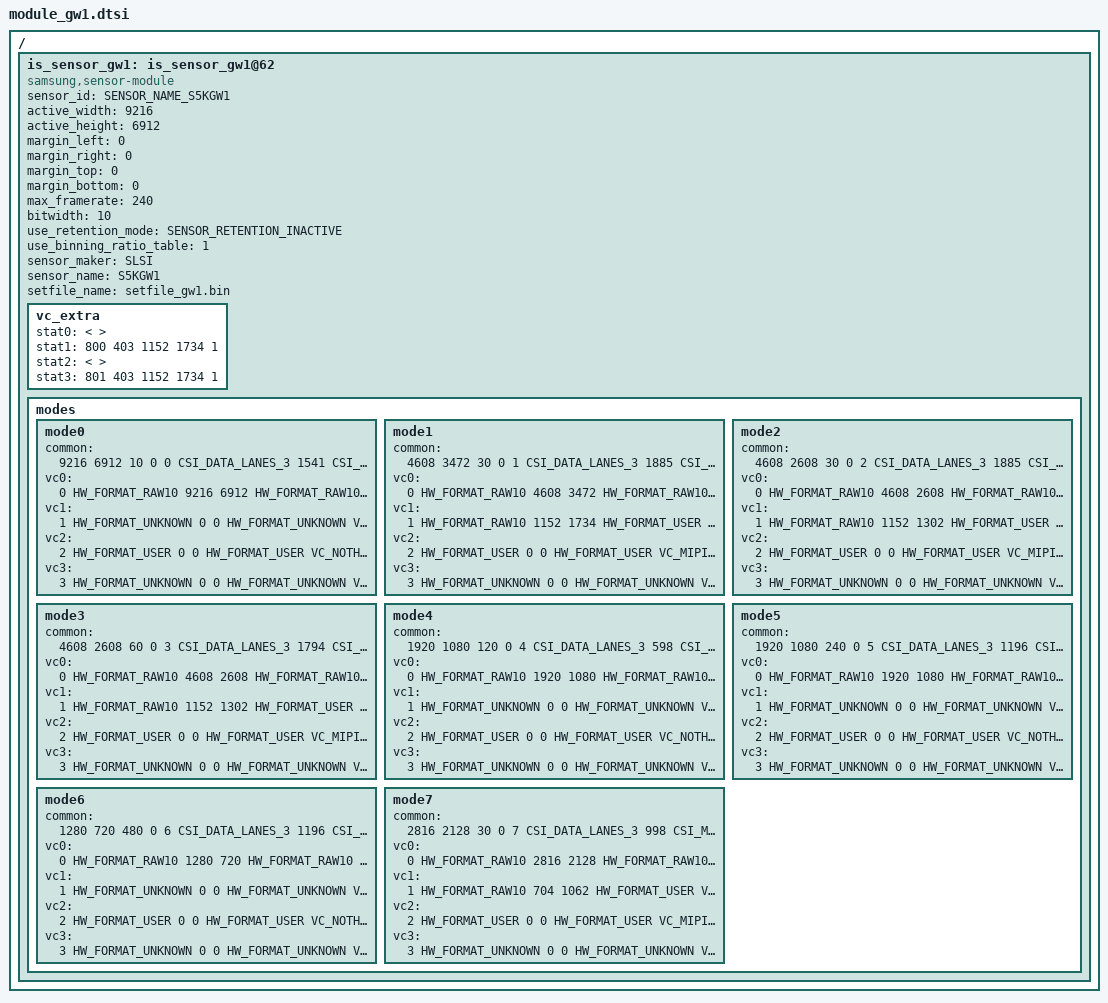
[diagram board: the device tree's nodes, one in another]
/*
 * SAMSUNG EXYNOSxxxx board camera device tree source
 *
 * Copyright (c) 2019 Samsung Electronics Co., Ltd.
 *		http://www.samsung.com
 *
 * This program is free software; you can redistribute it and/or modify
 * it under the terms of the GNU General Public License version 2 as
 * published by the Free Software Foundation.
 */

#include <dt-bindings/camera/exynos_is_dt.h>

/ {
	fragment@camera {
		target-path = "/";
		__overlay__ {
			is_sensor_gw1: is_sensor_gw1@62 {
				compatible = "samsung,sensor-module";

				/* common */
				sensor_id = <SENSOR_NAME_S5KGW1>;
				active_width = <9216>;
				active_height = <6912>;
				margin_left = <0>;
				margin_right = <0>;
				margin_top = <0>;
				margin_bottom = <0>;
				max_framerate = <240>;
				bitwidth = <10>;
				use_retention_mode = <SENSOR_RETENTION_INACTIVE>;
				use_binning_ratio_table = <1>;
				sensor_maker = "SLSI";
				sensor_name = "S5KGW1";
				setfile_name = "setfile_gw1.bin";

				status = "okay";

				vc_extra {
					/* ex) statX = <stat_type, sensor_mode, max_width, max_height, max_element> */
					stat0 = </* not avaliable */>;	/* VC_BUF_DATA_TYPE_SENSOR_STAT1 */
					stat1 = </* VC_STAT_TYPE_PDP_1_1_PDAF_STAT0 */ 800 /* VC_SENSOR_MODE_SUPER_PD_2_TAIL */ 403 1152 1734 1>; /* VC_BUF_DATA_TYPE_GENERAL_STAT1 */
					stat2 = </* not avaliable */>;	/* VC_BUF_DATA_TYPE_SENSOR_STAT2 */
					stat3 = </* VC_STAT_TYPE_PDP_1_1_PDAF_STAT1 */ 801 /* VC_SENSOR_MODE_SUPER_PD_2_TAIL */ 403 1152 1734 1>; /* VC_BUF_DATA_TYPE_GENERAL_STAT2 */
				};

				/* sensor modes */
				modes {
						/* common = <width, height, fps, settle, mode, lane, speed, interleave, pd_mode> */
						/* vcX = <map, hwformat, width, height, hwformat, type, width, height> */
					mode0 {
						common = <9216 6912 10 0 0 CSI_DATA_LANES_3 1541 CSI_MODE_VC_DT LRTE_DISABLE PD_NONE EX_NONE>;
						vc0 = </* in */ 0 HW_FORMAT_RAW10 9216 6912	/* out */ HW_FORMAT_RAW10 VC_NOTHING 9216 6912>;
						vc1 = </* in */ 1 HW_FORMAT_UNKNOWN 0 0		/* out */ HW_FORMAT_UNKNOWN VC_NOTHING 0 0>;
						vc2 = </* in */ 2 HW_FORMAT_USER 0 0		/* out */ HW_FORMAT_USER VC_NOTHING 0 0>;
						vc3 = </* in */ 3 HW_FORMAT_UNKNOWN 0 0		/* out */ HW_FORMAT_UNKNOWN VC_NOTHING 0 0>;
					};
					mode1 {
						common = <4608 3472 30 0 1 CSI_DATA_LANES_3 1885 CSI_MODE_VC_DT LRTE_DISABLE PD_MSPD_TAIL EX_NONE>;
						vc0 = </* in */ 0 HW_FORMAT_RAW10 4608 3472	/* out */ HW_FORMAT_RAW10 VC_NOTHING 4608 3472>;
						vc1 = </* in */ 1 HW_FORMAT_RAW10 1152 1734      /* out */ HW_FORMAT_USER VC_PRIVATE 1152 1734>;
						vc2 = </* in */ 2 HW_FORMAT_USER 0 0   /* out */ HW_FORMAT_USER VC_MIPISTAT 1152 1734>;
						vc3 = </* in */ 3 HW_FORMAT_UNKNOWN 0 0		/* out */ HW_FORMAT_UNKNOWN VC_NOTHING 0 0>;
					};
					mode2 {
						common = <4608 2608 30 0 2 CSI_DATA_LANES_3 1885 CSI_MODE_VC_DT LRTE_DISABLE PD_MSPD_TAIL EX_NONE>;
						vc0 = </* in */ 0 HW_FORMAT_RAW10 4608 2608	/* out */ HW_FORMAT_RAW10 VC_NOTHING 4608 2608>;
                        vc1 = </* in */ 1 HW_FORMAT_RAW10 1152 1302      /* out */ HW_FORMAT_USER VC_PRIVATE 1152 1302>;
                        vc2 = </* in */ 2 HW_FORMAT_USER 0 0   /* out */ HW_FORMAT_USER VC_MIPISTAT 1152 1302>;
						vc3 = </* in */ 3 HW_FORMAT_UNKNOWN 0 0		/* out */ HW_FORMAT_UNKNOWN VC_NOTHING 0 0>;
					};
					mode3 {
						common = <4608 2608 60 0 3 CSI_DATA_LANES_3 1794 CSI_MODE_VC_DT LRTE_DISABLE PD_MSPD_TAIL EX_NONE>;
						vc0 = </* in */ 0 HW_FORMAT_RAW10 4608 2608	/* out */ HW_FORMAT_RAW10 VC_NOTHING 4608 2608>;
						vc1 = </* in */ 1 HW_FORMAT_RAW10 1152 1302      /* out */ HW_FORMAT_USER VC_PRIVATE 1152 1302>;
						vc2 = </* in */ 2 HW_FORMAT_USER 0 0   /* out */ HW_FORMAT_USER VC_MIPISTAT 1152 1302>;
						vc3 = </* in */ 3 HW_FORMAT_UNKNOWN 0 0		/* out */ HW_FORMAT_UNKNOWN VC_NOTHING 0 0>;
					};
					mode4 {
						common = <1920 1080 120 0 4 CSI_DATA_LANES_3 598 CSI_MODE_VC_DT LRTE_DISABLE PD_NONE EX_NONE>;
						vc0 = </* in */ 0 HW_FORMAT_RAW10 1920 1080	/* out */ HW_FORMAT_RAW10 VC_NOTHING 1920 1080>;
						vc1 = </* in */ 1 HW_FORMAT_UNKNOWN 0 0		/* out */ HW_FORMAT_UNKNOWN VC_NOTHING 0 0>;
						vc2 = </* in */ 2 HW_FORMAT_USER 0 0		/* out */ HW_FORMAT_USER VC_NOTHING 0 0>;
						vc3 = </* in */ 3 HW_FORMAT_UNKNOWN 0 0		/* out */ HW_FORMAT_UNKNOWN VC_NOTHING 0 0>;
					};
					mode5 {
						common = <1920 1080 240 0 5 CSI_DATA_LANES_3 1196 CSI_MODE_VC_DT LRTE_DISABLE PD_NONE EX_NONE>;
						vc0 = </* in */ 0 HW_FORMAT_RAW10 1920 1080	/* out */ HW_FORMAT_RAW10 VC_NOTHING 1920 1080>;
						vc1 = </* in */ 1 HW_FORMAT_UNKNOWN 0 0		/* out */ HW_FORMAT_UNKNOWN VC_NOTHING 0 0>;
						vc2 = </* in */ 2 HW_FORMAT_USER 0 0		/* out */ HW_FORMAT_USER VC_NOTHING 0 0>;
						vc3 = </* in */ 3 HW_FORMAT_UNKNOWN 0 0		/* out */ HW_FORMAT_UNKNOWN VC_NOTHING 0 0>;
					};
					mode6 {
						common = <1280 720 480 0 6 CSI_DATA_LANES_3 1196 CSI_MODE_VC_DT LRTE_DISABLE PD_NONE EX_NONE>;
						vc0 = </* in */ 0 HW_FORMAT_RAW10 1280 720	/* out */ HW_FORMAT_RAW10 VC_NOTHING 1280 720>;
						vc1 = </* in */ 1 HW_FORMAT_UNKNOWN 0 0		/* out */ HW_FORMAT_UNKNOWN VC_NOTHING 0 0>;
						vc2 = </* in */ 2 HW_FORMAT_USER 0 0		/* out */ HW_FORMAT_USER VC_NOTHING 0 0>;
						vc3 = </* in */ 3 HW_FORMAT_UNKNOWN 0 0		/* out */ HW_FORMAT_UNKNOWN VC_NOTHING 0 0>;
					};
					mode7 {
						common = <2816 2128 30 0 7 CSI_DATA_LANES_3 998 CSI_MODE_VC_DT LRTE_DISABLE PD_MSPD_TAIL EX_NONE>;
						vc0 = </* in */ 0 HW_FORMAT_RAW10 2816 2128	/* out */ HW_FORMAT_RAW10 VC_NOTHING 2816 2128>;
						vc1 = </* in */ 1 HW_FORMAT_RAW10 704 1062      /* out */ HW_FORMAT_USER VC_PRIVATE 704 1062>;
						vc2 = </* in */ 2 HW_FORMAT_USER 0 0   /* out */ HW_FORMAT_USER VC_MIPISTAT 704 1062>;
						vc3 = </* in */ 3 HW_FORMAT_UNKNOWN 0 0		/* out */ HW_FORMAT_UNKNOWN VC_NOTHING 0 0>;
					};
				};

			};
		}; /* end of __overlay__ */
	}; /* end of fragment */
}; /* end of root */
